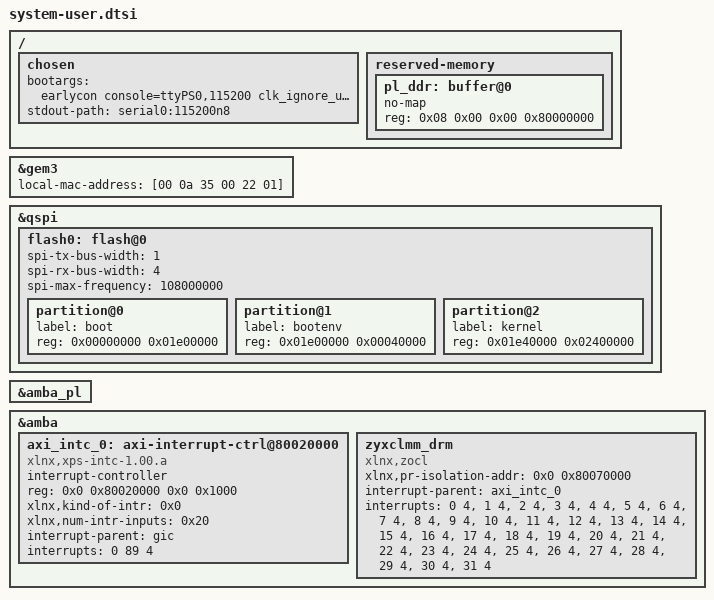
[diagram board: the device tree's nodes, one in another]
/* Copyright (C) 2020-2022 Xilinx, Inc. All rights reserved.
 * Copyright (C) 2022 Advanced Micro Devices, Inc. All rights reserved.
 *
 * Licensed under the Apache License, Version 2.0 (the "License");
 * you may not use this file except in compliance with the License.
 * You may obtain a copy of the License at
 *
 *     http://www.apache.org/licenses/LICENSE-2.0
 *
 * Unless required by applicable law or agreed to in writing, software
 * distributed under the License is distributed on an "AS IS" BASIS,
 * WITHOUT WARRANTIES OR CONDITIONS OF ANY KIND, either express or implied.
 * See the License for the specific language governing permissions and
 * limitations under the License.
 */

/*
 * /include/ "system-conf.dtsi"
 * Adding directly contents of system-conf file until CR-1139794 is fixed
 */
/ {
        chosen {
                bootargs = "earlycon console=ttyPS0,115200 clk_ignore_unused root=/dev/mmcblk0p2 rw rootwait cma=1536M";
                stdout-path = "serial0:115200n8";
        };
};

&gem3 {
        local-mac-address = [00 0a 35 00 22 01];
};

&qspi {
        #address-cells = <1>;
        #size-cells = <0>;
        flash0: flash@0 {
                spi-tx-bus-width=<1>;
                spi-rx-bus-width=<4>;
                spi-max-frequency = <108000000>;
                /delete-node/ partition@0;
                /delete-node/ partition@100000;
                /delete-node/ partition@600000;
                /delete-node/ partition@620000;
                partition@0 {
                        label = "boot";
                        reg = <0x00000000 0x01e00000>;
                };
                partition@1 {
                        label = "bootenv";
                        reg = <0x01e00000 0x00040000>;
                };
                partition@2 {
                        label = "kernel";
                        reg = <0x01e40000 0x02400000>;
                };
        };
};

/{
	reserved-memory {
                #address-cells = <2>;
                #size-cells = <2>;
                ranges;
                pl_ddr: buffer@0 {
                        no-map;
                        reg = <0x08 0x00 0x00 0x80000000>;
                };
        };
};

&amba_pl {
	/delete-node/ interrupt-controller@80020000;
};

&amba {
	axi_intc_0: axi-interrupt-ctrl@80020000 {
		#interrupt-cells = <2>;
		compatible = "xlnx,xps-intc-1.00.a";
		interrupt-controller;
		reg = <0x0 0x80020000 0x0 0x1000>;
		xlnx,kind-of-intr = <0x0>;
		xlnx,num-intr-inputs = <0x20>;
		interrupt-parent = <&gic>;
		interrupts = <0 89 4>;
	};

	zyxclmm_drm {
		compatible = "xlnx,zocl";
		status = "okay";
		xlnx,pr-isolation-addr = <0x0 0x80070000>;
		interrupt-parent = <&axi_intc_0>;
		interrupts = <0  4>, <1  4>, <2  4>, <3  4>,
			     <4  4>, <5  4>, <6  4>, <7  4>,
			     <8  4>, <9  4>, <10 4>, <11 4>,
			     <12 4>, <13 4>, <14 4>, <15 4>,
			     <16 4>, <17 4>, <18 4>, <19 4>,
			     <20 4>, <21 4>, <22 4>, <23 4>,
			     <24 4>, <25 4>, <26 4>, <27 4>,
			     <28 4>, <29 4>, <30 4>, <31 4>;
	};
};

